# GD32E502 register map
File version: 1.0
CPU: CM33 r0p4, little endian, MPU, FPU, 4 interrupt priority bits
Registers are 32-bit, read-write, reset 0x0 unless marked. A register's access mark holds for its fields unless they carry their own. Offsets are from the block's base; [hi:lo] are bit positions.

## DBG — Debug support
Base 0xE0044000
0x00 ID ro — ID code register
  [31:0] ID_CODE — DBG ID code register
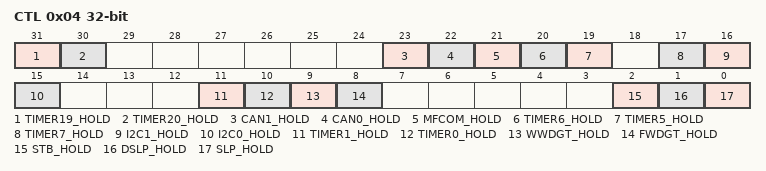
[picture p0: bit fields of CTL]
0x04 CTL — Control register
  [31] TIMER19_HOLD — TIMER19 hold bit
  [30] TIMER20_HOLD — TIMER20 hold bit
  [23] CAN1_HOLD — CAN1 hold bit
  [22] CAN0_HOLD — CAN0 hold bit
  [21] MFCOM_HOLD — MFCOM hold bit
  [20] TIMER6_HOLD — TIMER 6 hold bit
  [19] TIMER5_HOLD — TIMER 5 hold bit
  [17] TIMER7_HOLD — TIMER 7 hold bit
  [16] I2C1_HOLD — I2C1 hold bit
  [15] I2C0_HOLD — I2C0 hold bit
  [11] TIMER1_HOLD — TIMER 1 hold bit
  [10] TIMER0_HOLD — TIMER 0 hold bit
  [9] WWDGT_HOLD — WWDGT hold bit
  [8] FWDGT_HOLD — FWDGT hold bit
  [2] STB_HOLD — Standby mode hold bit
  [1] DSLP_HOLD — Deep-sleep mode hold bit
  [0] SLP_HOLD — Sleep mode hold bit

## FWDGT — free watchdog timer
Base 0x40003000
0x00 CTL wo — Control register
  [15:0] CMD — Key value
0x04 PSC — Prescaler register
  [2:0] PSC — Prescaler divider
0x08 RLD reset 0xFFF — Reload register
  [11:0] RLD — Free watchdog timer counter reload value
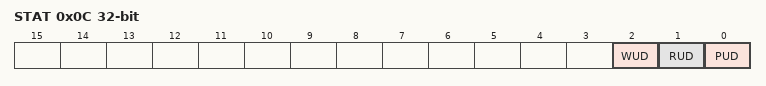
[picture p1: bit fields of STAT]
0x0C STAT ro — Status register
  [2] WUD — Watchdog counter window value update
  [1] RUD — Free watchdog timer counter reload value update
  [0] PUD — Free watchdog timer prescaler value update
0x10 WND reset 0xFFF — Window register
  [11:0] WND — Watchdog counter window value

## WWDGT — Window watchdog timer
Base 0x40002C00
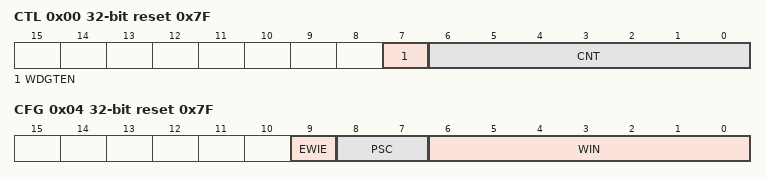
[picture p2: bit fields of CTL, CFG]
0x00 CTL reset 0x7F — Control register
  [7] WDGTEN — Activation bit
  [6:0] CNT — 7-bit counter
0x04 CFG reset 0x7F — Configuration register
  [9] EWIE — Early wakeup interrupt
  [8:7] PSC — Prescaler
  [6:0] WIN — 7-bit window value
0x08 STAT — Status register
  [0] EWIF — Early wakeup interrupt flag

## RTC — Real-time clock
Base 0x40002800
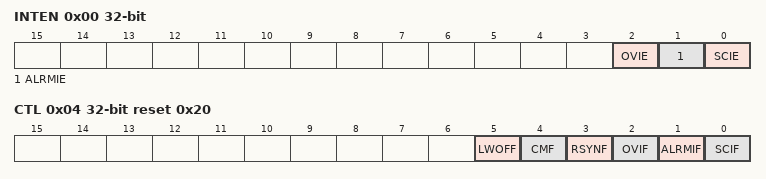
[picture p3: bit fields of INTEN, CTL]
0x00 INTEN — RTC interrupt enable register
  [2] OVIE — Overflow interrupt enable
  [1] ALRMIE — Alarm interrupt enable
  [0] SCIE — Second interrupt
0x04 CTL access per field reset 0x20 — control register
  [5] LWOFF ro — Last write operation finished flag
  [4] CMF rw — Configuration mode flag
  [3] RSYNF rw — Registers synchronized flag
  [2] OVIF rw — Overflow interrupt flag
  [1] ALRMIF rw — Alarm interrupt flag
  [0] SCIF rw — Sencond interrupt flag
0x08 PSCH wo — RTC prescaler high register
  [3:0] PSC — RTC prescaler value high
0x0C PSCL wo reset 0x8000 — RTC prescaler low register
  [15:0] PSC — RTC prescaler value low
0x10 DIVH ro — RTC divider high register
  [3:0] DIV — RTC divider value high
0x14 DIVL ro reset 0x8000 — RTC divider low register
  [15:0] DIV — RTC divider value low
0x18 CNTH — RTC counter high register
  [15:0] CNT — RTC counter value high
0x1C CNTL — RTC counter low register
  [15:0] CNT — RTC conuter value low
0x20 ALRMH wo reset 0xFFFF — Alarm high register
  [15:0] ALRM — Alarm value high
0x24 ALRML wo reset 0xFFFF — RTC alarm low register
  [15:0] ALRM — alarm value low

## TIMER5 — Basic-timers
Base 0x40001000
Same registers: TIMER6 0x40001400
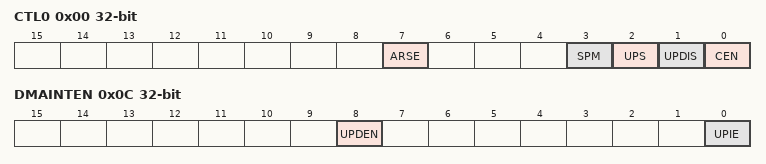
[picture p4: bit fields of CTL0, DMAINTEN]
0x00 CTL0 — control register 0
  [7] ARSE — Auto-reload shadow enable
  [3] SPM — Single pulse mode
  [2] UPS — Update source
  [1] UPDIS — Update disable
  [0] CEN — Counter enable
0x04 CTL1 — control register 1
  [6:4] MMC — Master mode control
0x0C DMAINTEN — DMA/Interrupt enable register
  [8] UPDEN — Update DMA request enable
  [0] UPIE — Update interrupt enable
0x10 INTF — Interrupt flag register
  [0] UPIF — Update interrupt flag
0x14 SWEVG wo — event generation register
  [0] UPG — Update generation
0x24 CNT — Counter register
  [15:0] CNT — Low counter value
0x28 PSC — Prescaler register
  [15:0] PSC — Prescaler value of the counter clock
0x2C CAR — Counter auto reload register
  [15:0] CARL — Counter auto reload value
